# EFR32BG21B010F1024IM32 register map
Vendor: Silicon Labs; Series: EFR32; File version: B
Registers are 32-bit, read-write, reset 0x0 unless marked. A register's access mark holds for its fields unless they carry their own. Offsets are from the block's base; [hi:lo] are bit positions; lines under a group give offsets from that group; {n}, {i} and the like mark numbered series; 'fields as' and 'values as' point back to an identical list.

## GPIO_S — GPIO_S Registers
Base 0x4003C000
Same registers: GPIO_NS 0x5003C000
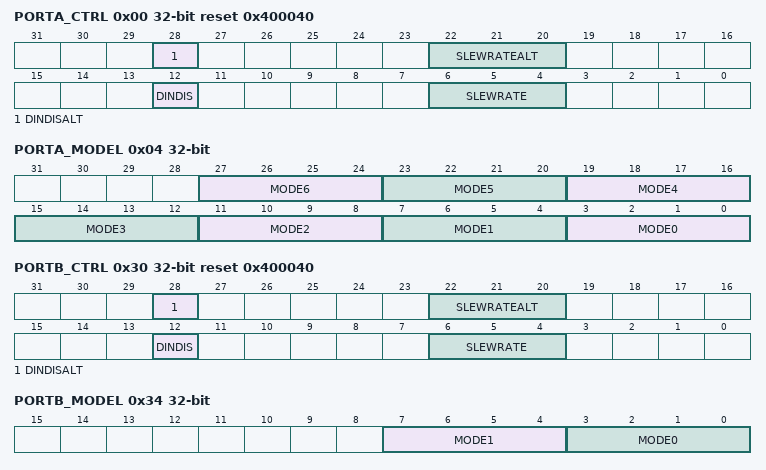
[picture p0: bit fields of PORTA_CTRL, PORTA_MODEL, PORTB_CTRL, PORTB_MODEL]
0x00 PORTA_CTRL reset 0x400040 — Port control
  [28] DINDISALT — Data In Disable Alt
  [22:20] SLEWRATEALT
  [12] DINDIS — Data In Disable
  [6:4] SLEWRATE
0x04 PORTA_MODEL — mode low
  [all] fields
    0=DISABLED (Input disabled. Pullup if DOUT is set.); 1=INPUT (Input enabled. Filter if DOUT is set.); 2=INPUTPULL (Input enabled. DOUT determines pull direction.); 3=INPUTPULLFILTER (Input enabled with filter. DOUT determines pull direction.); 4=PUSHPULL (Push-pull output.); 5=PUSHPULLALT (Push-pull using alternate control.); 6=WIREDOR (Wired-or output.); 7=WIREDORPULLDOWN (Wired-or output with pull-down.); 8=WIREDAND (Open-drain output.); 9=WIREDANDFILTER (Open-drain output with filter.); 10=WIREDANDPULLUP (Open-drain output with pullup.); 11=WIREDANDPULLUPFILTER (Open-drain output with filter and pullup.); 12=WIREDANDALT (Open-drain output using alternate control.); 13=WIREDANDALTFILTER (Open-drain output using alternate control with filter.); 14=WIREDANDALTPULLUP (Open-drain output using alternate control with pullup.); 15=WIREDANDALTPULLUPFILTER (Open-drain output using alternate control with filter and pullup.)
  [4n+3:4n] MODE{n} (n=0..6) — MODE n
0x10 PORTA_DOUT — data out
  [6:0] DOUT — Data output
0x14 PORTA_DIN ro — data in
  [6:0] DIN — Data input
0x30 PORTB_CTRL reset 0x400040 — Port control
  fields as PORTA_CTRL
0x34 PORTB_MODEL — mode low
  [7:4] MODE1 — MODE n
    values as the fields of PORTA_MODEL
  [3:0] MODE0 — MODE n
    values as the fields of PORTA_MODEL
0x40 PORTB_DOUT — data out
  [1:0] DOUT — Data output
0x44 PORTB_DIN ro — data in
  [1:0] DIN — Data input
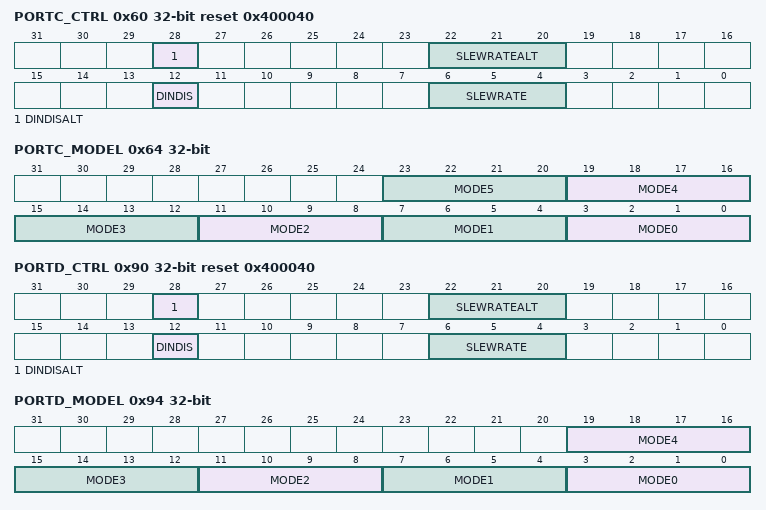
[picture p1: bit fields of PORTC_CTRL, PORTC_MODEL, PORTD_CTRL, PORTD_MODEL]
0x60 PORTC_CTRL reset 0x400040 — Port control
  fields as PORTA_CTRL
0x64 PORTC_MODEL — mode low
  [all] fields
    values as the fields of PORTA_MODEL
  [4n+3:4n] MODE{n} (n=0..5) — MODE n
0x70 PORTC_DOUT — data out
  [5:0] DOUT — Data output
0x74 PORTC_DIN ro — data in
  [5:0] DIN — Data input
0x90 PORTD_CTRL reset 0x400040 — Port control
  fields as PORTA_CTRL
0x94 PORTD_MODEL — mode low
  [all] fields
    values as the fields of PORTA_MODEL
  [4n+3:4n] MODE{n} (n=0..4) — MODE n
0xA0 PORTD_DOUT — data out
  [4:0] DOUT — Data output
0xA4 PORTD_DIN ro — data in
  [4:0] DIN — Data input
0x300 LOCK wo reset 0xA534
  [15:0] LOCKKEY — Configuration Lock Key
    0xA534=UNLOCK
0x310 GPIOLOCKSTATUS ro
  [0] LOCK — GPIO LOCK Status
    0=UNLOCKED; 1=LOCKED
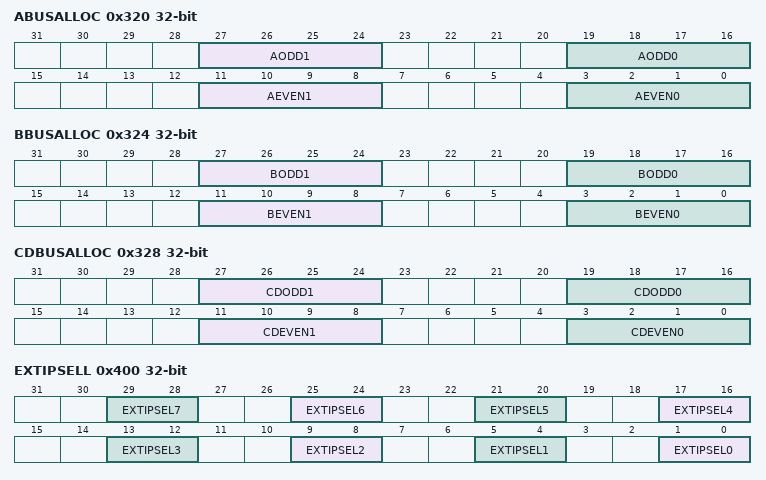
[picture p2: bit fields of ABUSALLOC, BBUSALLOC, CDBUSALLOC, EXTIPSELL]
0x320 ABUSALLOC — A Bus allocation
  [all] fields
    0=TRISTATE (The bus is not allocated); 1=ADC0 (The bus is allocated to ADC0); 2=ACMP0 (The bus is allocated to ACMP0); 3=ACMP1 (The bus is allocated to ACMP1)
  [27:24] AODD1 — A Bus Odd 1
  [19:16] AODD0 — A Bus Odd 0
  [11:8] AEVEN1 — A Bus Even 1
  [3:0] AEVEN0 — A Bus Even 0
0x324 BBUSALLOC — B Bus allocation
  [all] fields
    values as the fields of ABUSALLOC
  [27:24] BODD1 — B Bus Odd 1
  [19:16] BODD0 — B Bus Odd 0
  [11:8] BEVEN1 — B Bus Even 1
  [3:0] BEVEN0 — B Bus Even 0
0x328 CDBUSALLOC — CD Bus allocation
  [all] fields
    values as the fields of ABUSALLOC
  [27:24] CDODD1 — CD Bus Odd 1
  [19:16] CDODD0 — CD Bus Odd 0
  [11:8] CDEVEN1 — CD Bus Even 1
  [3:0] CDEVEN0 — CD Bus Even 0
0x400 EXTIPSELL — External Interrupt Port Select Low
  [all] fields
    0=PORTA (Port A group selected); 1=PORTB (Port B group selected); 2=PORTC (Port C group selected); 3=PORTD (Port D group selected)
  [4n+1:4n] EXTIPSEL{n} (n=0..7) — External Interrupt Port Select
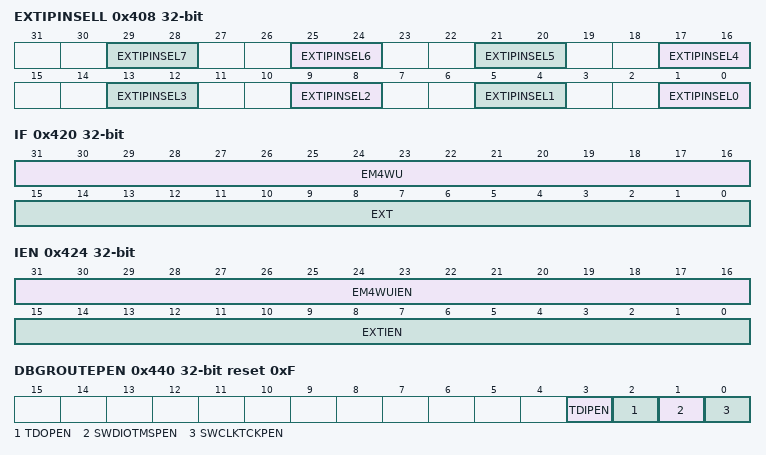
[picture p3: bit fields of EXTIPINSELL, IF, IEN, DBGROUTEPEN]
0x408 EXTIPINSELL — External Interrupt Pin Select Low
  [all] fields
    {v}=OFFSET{v} (v=0..3)
  [4n+1:4n] EXTIPINSEL{n} (n=0..7) — External Interrupt Pin select
0x410 EXTIRISE — External Interrupt Rising Edge Trigger
  [7:0] EXTIRISE — EXT Int Rise
0x414 EXTIFALL — External Interrupt Falling Edge Trigger
  [7:0] EXTIFALL — EXT Int FALL
0x420 IF — Interrupt Flag
  [31:16] EM4WU — EM4 wake up
  [15:0] EXT — External Pin Flag
0x424 IEN — Interrupt Enable
  [31:16] EM4WUIEN — EM4 Wake Up Interrupt En
  [15:0] EXTIEN — External Pin Enable
0x42C EM4WUEN
  [27:16] EM4WUEN — EM4 wake up enable
0x430 EM4WUPOL
  [27:16] EM4WUPOL — EM4 Wake-Up Polarity
0x440 DBGROUTEPEN reset 0xF
  [3] TDIPEN — JTAG Test Debug Input Pin Enable
  [2] TDOPEN — JTAG Test Debug Output Pin Enable
  [1] SWDIOTMSPEN — Route Location 0
  [0] SWCLKTCKPEN — Route Pin Enable
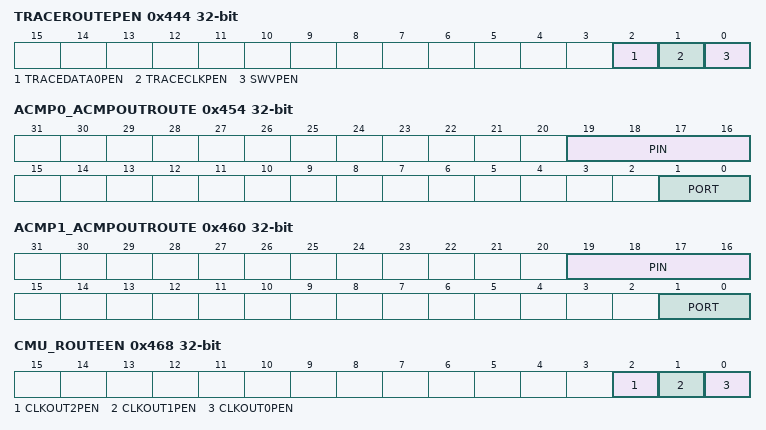
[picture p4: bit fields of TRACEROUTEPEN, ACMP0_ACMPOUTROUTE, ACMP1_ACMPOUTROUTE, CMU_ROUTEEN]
0x444 TRACEROUTEPEN
  [2] TRACEDATA0PEN — Trace Data0 Pin Enable
  [1] TRACECLKPEN — Trace Clk Pin Enable
  [0] SWVPEN — Serial Wire Viewer Output Pin Enable
0x450 ACMP0_ROUTEEN
  [0] ACMPOUTPEN — ACMPOUT pin enable control bit
0x454 ACMP0_ACMPOUTROUTE
  [19:16] PIN — ACMPOUT pin select register
  [1:0] PORT — ACMPOUT port select register
0x45C ACMP1_ROUTEEN
  [0] ACMPOUTPEN — ACMPOUT pin enable control bit
0x460 ACMP1_ACMPOUTROUTE
  fields as ACMP0_ACMPOUTROUTE
0x468 CMU_ROUTEEN
  [2] CLKOUT2PEN — CLKOUT2 pin enable control bit
  [1] CLKOUT1PEN — CLKOUT1 pin enable control bit
  [0] CLKOUT0PEN — CLKOUT0 pin enable control bit
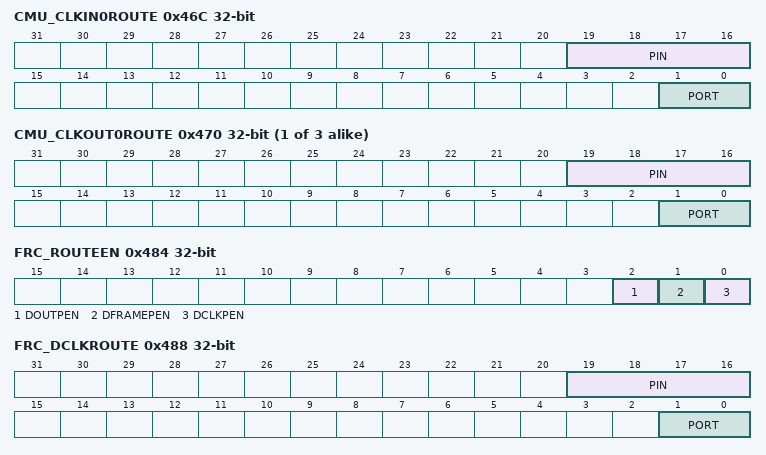
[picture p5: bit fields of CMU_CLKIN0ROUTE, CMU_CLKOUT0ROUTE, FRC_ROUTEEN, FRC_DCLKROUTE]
0x46C CMU_CLKIN0ROUTE
  [19:16] PIN — CLKIN0 pin select register
  [1:0] PORT — CLKIN0 port select register
{0x470+4i} CMU_CLKOUT{i}ROUTE (i=0..2)
  [19:16] PIN — CLKOUT{i} pin select register
  [1:0] PORT — CLKOUT{i} port select register
0x484 FRC_ROUTEEN
  [2] DOUTPEN — DOUT pin enable control bit
  [1] DFRAMEPEN — DFRAME pin enable control bit
  [0] DCLKPEN — DCLK pin enable control bit
0x488 FRC_DCLKROUTE
  [19:16] PIN — DCLK pin select register
  [1:0] PORT — DCLK port select register
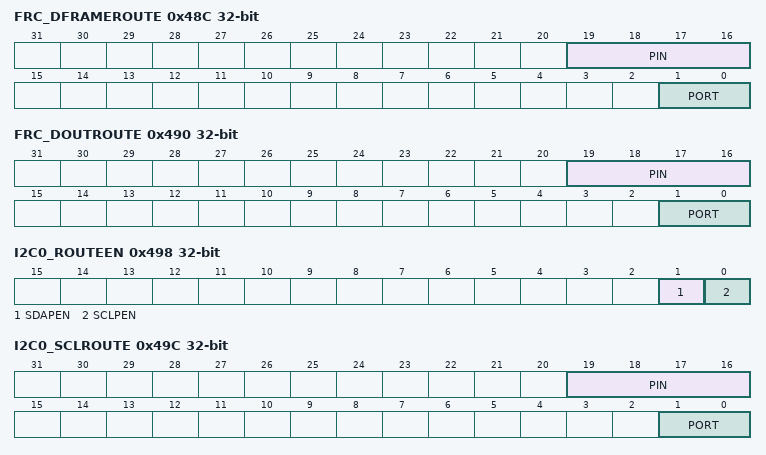
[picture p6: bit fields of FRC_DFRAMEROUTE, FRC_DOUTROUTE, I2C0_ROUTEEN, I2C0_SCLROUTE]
0x48C FRC_DFRAMEROUTE
  [19:16] PIN — DFRAME pin select register
  [1:0] PORT — DFRAME port select register
0x490 FRC_DOUTROUTE
  [19:16] PIN — DOUT pin select register
  [1:0] PORT — DOUT port select register
0x498 I2C0_ROUTEEN
  [1] SDAPEN — SDA pin enable control bit
  [0] SCLPEN — SCL pin enable control bit
0x49C I2C0_SCLROUTE
  [19:16] PIN — SCL pin select register
  [1:0] PORT — SCL port select register
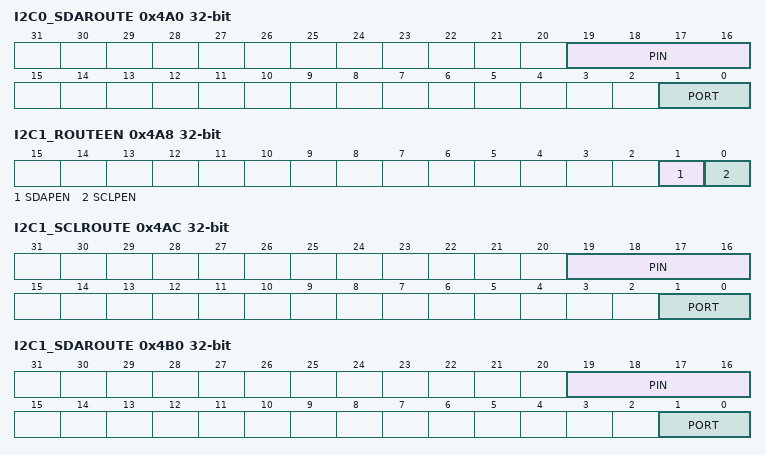
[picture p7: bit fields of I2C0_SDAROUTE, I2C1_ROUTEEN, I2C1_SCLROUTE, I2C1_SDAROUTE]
0x4A0 I2C0_SDAROUTE
  [19:16] PIN — SDA pin select register
  [1:0] PORT — SDA port select register
0x4A8 I2C1_ROUTEEN
  fields as I2C0_ROUTEEN
0x4AC I2C1_SCLROUTE
  fields as I2C0_SCLROUTE
0x4B0 I2C1_SDAROUTE
  fields as I2C0_SDAROUTE
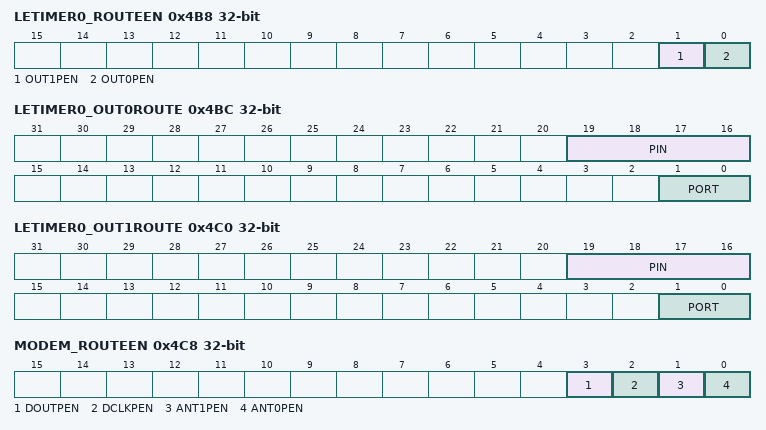
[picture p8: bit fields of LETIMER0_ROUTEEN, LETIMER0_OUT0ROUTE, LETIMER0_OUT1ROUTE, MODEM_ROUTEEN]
0x4B8 LETIMER0_ROUTEEN
  [1] OUT1PEN — OUT1 pin enable control bit
  [0] OUT0PEN — OUT0 pin enable control bit
0x4BC LETIMER0_OUT0ROUTE
  [19:16] PIN — OUT0 pin select register
  [1:0] PORT — OUT0 port select register
0x4C0 LETIMER0_OUT1ROUTE
  [19:16] PIN — OUT1 pin select register
  [1:0] PORT — OUT1 port select register
0x4C8 MODEM_ROUTEEN
  [3] DOUTPEN — DOUT pin enable control bit
  [2] DCLKPEN — DCLK pin enable control bit
  [1] ANT1PEN — ANT1 pin enable control bit
  [0] ANT0PEN — ANT0 pin enable control bit
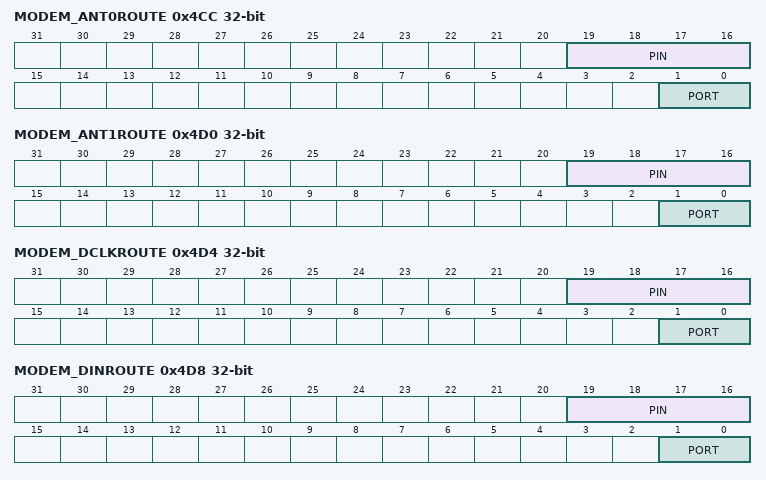
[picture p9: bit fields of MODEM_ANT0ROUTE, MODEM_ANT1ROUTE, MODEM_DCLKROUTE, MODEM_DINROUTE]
0x4CC MODEM_ANT0ROUTE
  [19:16] PIN — ANT0 pin select register
  [1:0] PORT — ANT0 port select register
0x4D0 MODEM_ANT1ROUTE
  [19:16] PIN — ANT1 pin select register
  [1:0] PORT — ANT1 port select register
0x4D4 MODEM_DCLKROUTE
  fields as FRC_DCLKROUTE
0x4D8 MODEM_DINROUTE
  [19:16] PIN — DIN pin select register
  [1:0] PORT — DIN port select register
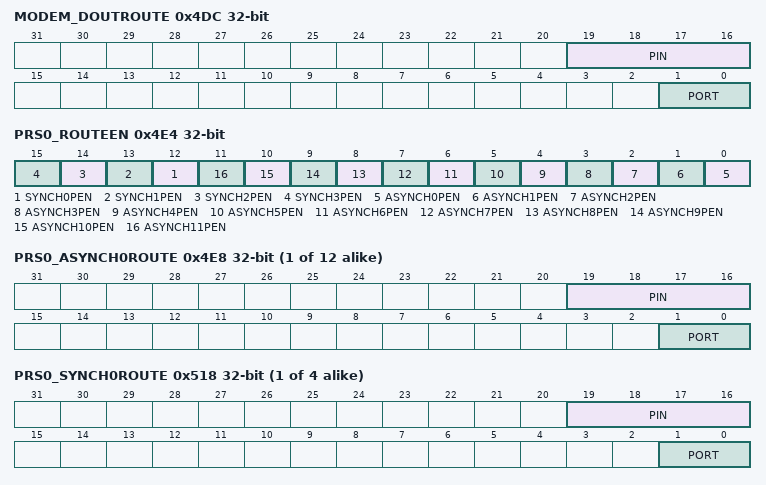
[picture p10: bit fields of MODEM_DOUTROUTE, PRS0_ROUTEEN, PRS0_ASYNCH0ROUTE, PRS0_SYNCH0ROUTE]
0x4DC MODEM_DOUTROUTE
  fields as FRC_DOUTROUTE
0x4E4 PRS0_ROUTEEN
  [n+12] SYNCH{n}PEN (n=0..3) — SYNCH{n} pin enable control bit
  [n] ASYNCH{n}PEN (n=0..11) — ASYNCH{n} pin enable control bit
{0x4E8+4i} PRS0_ASYNCH{i}ROUTE (i=0..11)
  [19:16] PIN — ASYNCH{i} pin select register
  [1:0] PORT — ASYNCH{i} port select register
{0x518+4i} PRS0_SYNCH{i}ROUTE (i=0..3)
  [19:16] PIN — SYNCH{i} pin select register
  [1:0] PORT — SYNCH{i} port select register
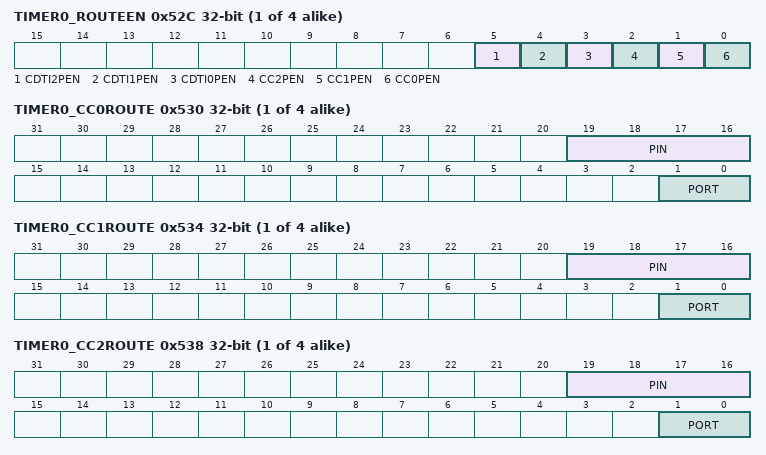
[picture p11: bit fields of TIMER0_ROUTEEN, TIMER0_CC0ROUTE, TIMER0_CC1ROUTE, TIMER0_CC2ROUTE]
{0x52C+0x20*i} TIMER{i}_ROUTEEN (i=0..3)
  [5] CDTI2PEN — CDTI2 pin enable control bit
  [4] CDTI1PEN — CDTI1 pin enable control bit
  [3] CDTI0PEN — CDTI0 pin enable control bit
  [2] CC2PEN — CC2 pin enable control bit
  [1] CC1PEN — CC1 pin enable control bit
  [0] CC0PEN — CC0 pin enable control bit
{0x530+0x20*i} TIMER{i}_CC0ROUTE (i=0..3)
  [19:16] PIN — CC0 pin select register
  [1:0] PORT — CC0 port select register
{0x534+0x20*i} TIMER{i}_CC1ROUTE (i=0..3)
  [19:16] PIN — CC1 pin select register
  [1:0] PORT — CC1 port select register
{0x538+0x20*i} TIMER{i}_CC2ROUTE (i=0..3)
  [19:16] PIN — CC2 pin select register
  [1:0] PORT — CC2 port select register
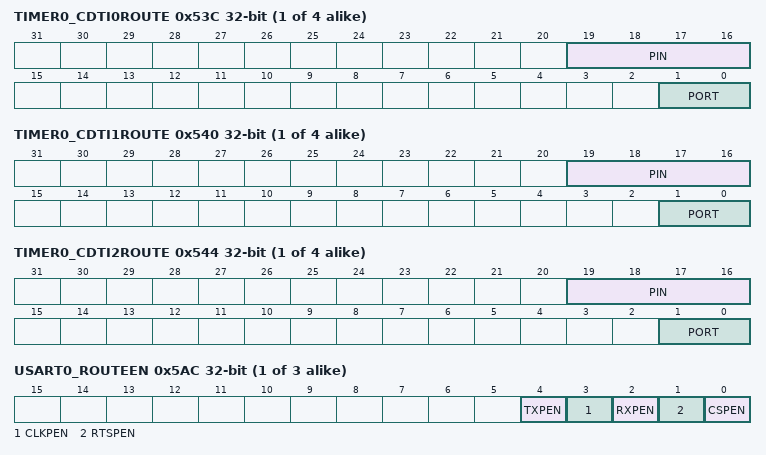
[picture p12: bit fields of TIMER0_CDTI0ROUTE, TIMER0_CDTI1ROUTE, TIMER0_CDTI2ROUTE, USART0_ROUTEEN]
{0x53C+0x20*i} TIMER{i}_CDTI0ROUTE (i=0..3)
  [19:16] PIN — CCC0 pin select register
  [1:0] PORT — CCC0 port select register
{0x540+0x20*i} TIMER{i}_CDTI1ROUTE (i=0..3)
  [19:16] PIN — CCC1 pin select register
  [1:0] PORT — CCC1 port select register
{0x544+0x20*i} TIMER{i}_CDTI2ROUTE (i=0..3)
  [19:16] PIN — CCC2 pin select register
  [1:0] PORT — CCC2 port select register
{0x5AC+0x20*i} USART{i}_ROUTEEN (i=0..2)
  [4] TXPEN — TX pin enable control bit
  [3] CLKPEN — CLK pin enable control bit
  [2] RXPEN — RX pin enable control bit
  [1] RTSPEN — RTS pin enable control bit
  [0] CSPEN — CS pin enable control bit
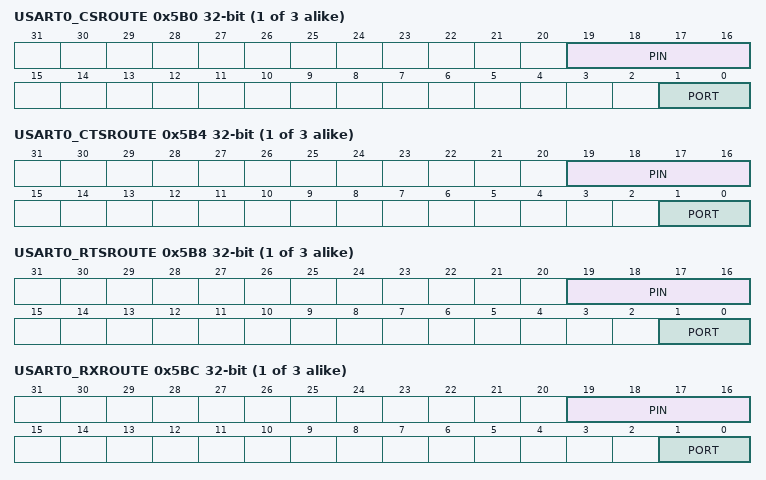
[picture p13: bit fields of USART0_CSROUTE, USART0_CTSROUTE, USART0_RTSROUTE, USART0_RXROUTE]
{0x5B0+0x20*i} USART{i}_CSROUTE (i=0..2)
  [19:16] PIN — CS pin select register
  [1:0] PORT — CS port select register
{0x5B4+0x20*i} USART{i}_CTSROUTE (i=0..2)
  [19:16] PIN — CTS pin select register
  [1:0] PORT — CTS port select register
{0x5B8+0x20*i} USART{i}_RTSROUTE (i=0..2)
  [19:16] PIN — RTS pin select register
  [1:0] PORT — RTS port select register
{0x5BC+0x20*i} USART{i}_RXROUTE (i=0..2)
  [19:16] PIN — RX pin select register
  [1:0] PORT — RX port select register
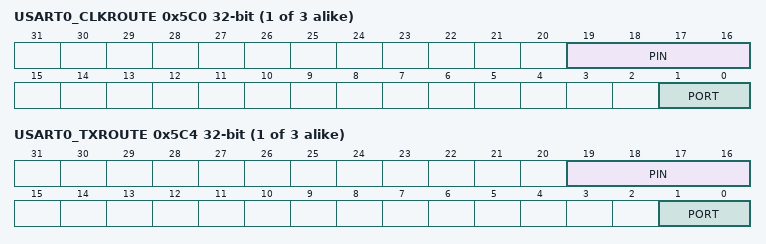
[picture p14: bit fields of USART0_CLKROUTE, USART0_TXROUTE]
{0x5C0+0x20*i} USART{i}_CLKROUTE (i=0..2)
  [19:16] PIN — SCLK pin select register
  [1:0] PORT — SCLK port select register
{0x5C4+0x20*i} USART{i}_TXROUTE (i=0..2)
  [19:16] PIN — TX pin select register
  [1:0] PORT — TX port select register
